# SAM9X75D5M device description
Architecture: ARM926EJ-S; Family: SAM9; Series: SAM9X7
Registers are 32-bit, read-write, reset 0x0 unless marked. A register's access mark holds for its fields unless they carry their own. Offsets are from the block's base; [hi:lo] are bit positions; {n}, {i} and the like mark numbered series; 'fields as' and 'values as' point back to an identical list.

## DSI — LCD Controller
Instances: DSI 0xF8054000
0x04 DSI_PWR_UP — Power-Up Control Register
  [0] SHUTDOWNZ — Shutdown
    0=DSI host is reset; 1=DSI host is powered up
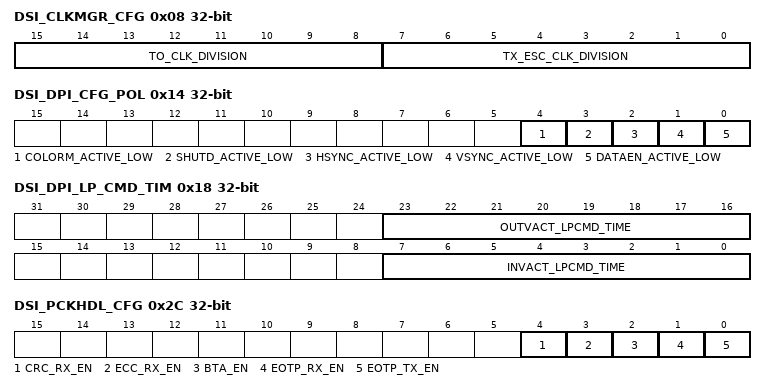
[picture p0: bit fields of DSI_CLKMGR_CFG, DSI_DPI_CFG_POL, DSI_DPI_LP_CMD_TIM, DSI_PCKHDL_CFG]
0x08 DSI_CLKMGR_CFG — Clock Management Configuration Register
  [15:8] TO_CLK_DIVISION — Timeout Clock Division
  [7:0] TX_ESC_CLK_DIVISION — Transmission Escape Clock Division
0x0C DSI_DPI_VCID — Input Video Virtual Channel ID Configuration Register
  [1:0] DPI_VCID — Input Video Virtual Channel Identifier
0x10 DSI_DPI_COLOR_CODING — Input Video Color Coding Configuration Register
  [3:0] DPI_COLOR_CODING — Input Video Color Coding
    0=16BIT_CFG1 (16-bit configuration 1); 1=16BIT_CFG2 (16-bit configuration 2); 2=16BIT_CFG3 (16-bit configuration 3); 3=18BIT_CFG1 (18-bit configuration 1); 4=18BIT_CFG2 (18-bit configuration 2); 5=24BIT
0x14 DSI_DPI_CFG_POL — Input Video Polarity Configuration Register
  [4] COLORM_ACTIVE_LOW — Color Mode Signal Active Low
    0=Input interface Color Mode signal is active high; 1=Input interface Color Mode signal is active low
  [3] SHUTD_ACTIVE_LOW — Shutdown Signal Active Low
    0=Input interface Shutdown signal is active high; 1=Input interface Shutdown signal is active low
  [2] HSYNC_ACTIVE_LOW — Horizontal Synchronisation Signal Active Low
    0=Input video interface VSYNC is active high; 1=Input video interface VSYNC is active low
  [1] VSYNC_ACTIVE_LOW — Vertical Synchronisation Signal Active Low
    values as HSYNC_ACTIVE_LOW
  [0] DATAEN_ACTIVE_LOW — Data Enable Signal Active Low
    0=Input video interface DATAEN is active high; 1=Input video interface DATAEN is active low
0x18 DSI_DPI_LP_CMD_TIM — Input Video Timing for Low-Power Commands Configuration Register
  [23:16] OUTVACT_LPCMD_TIME — Output Vertical Active Low-Power Command
  [7:0] INVACT_LPCMD_TIME — Input Vertical Active Low-Power Command Time
0x2C DSI_PCKHDL_CFG — DSI Protocol Configuration Register
  [4] CRC_RX_EN — CRC Reception Enable
    0=Disables the CRC reception and error reporting; 1=Enables the CRC reception and error reporting
  [3] ECC_RX_EN — ECC Reception Enable
    0=Disables the ECC reception, error correction, and reporting; 1=Enables the ECC reception, error correction, and reporting
  [2] BTA_EN — Bus Turn-Around Enable
    0=Disables the Bus Turnaround (BTA) request; 1=Enables the Bus Turnaround (BTA) request
  [1] EOTP_RX_EN — End Of Reception Packet Enable
    0=Disables the EoTp reception; 1=Enables the EoTp reception
  [0] EOTP_TX_EN — End Of Transmission Packet Enable
    0=Disables the EoTp transmission; 1=Enables the EoTp transmission
0x30 DSI_GEN_VCID — Read Generic Virtual Channel ID Configuration Register
  [1:0] GEN_VCID_RX — Generic Reception Virtual Channel Identifier
0x34 DSI_MODE_CFG — Mode of Operation Configuration Register
  [0] CMD_VIDEO_MODE — Command/Video Mode
    0=Video mode; 1=Command mode
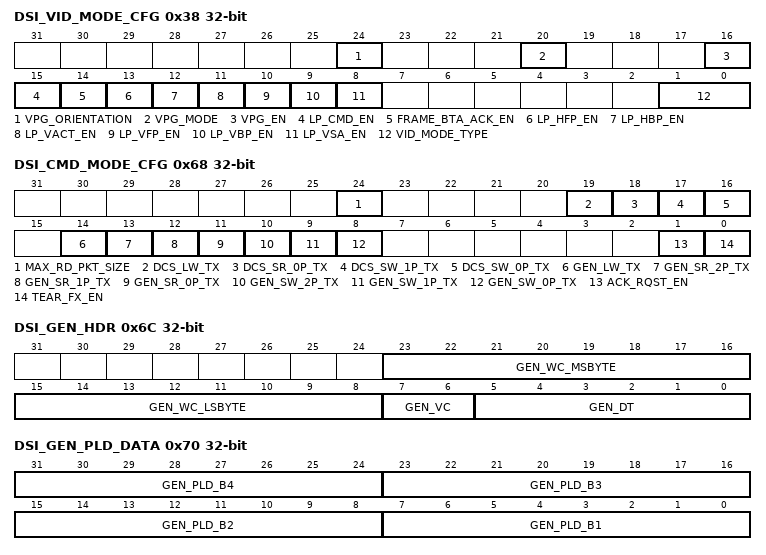
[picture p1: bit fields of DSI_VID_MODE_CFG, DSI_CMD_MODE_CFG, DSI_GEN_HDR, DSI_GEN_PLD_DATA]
0x38 DSI_VID_MODE_CFG — Video Mode Configuration Register
  [24] VPG_ORIENTATION — Video Pattern Generator Orientation
    0=Vertical color bar orientation; 1=Horizontal color bar orientation
  [20] VPG_MODE — Video Pattern Generator Mode
    0=Color bar (horizontal or vertical) pattern is selected; 1=BER pattern (vertical only) is selected
  [16] VPG_EN — Video Pattern Generator Enable
    0=Disables the video mode pattern generator; 1=Enables the video mode pattern generator
  [15] LP_CMD_EN — Low Power Command Transmission Enable
    0=Disables the command transmission only in Low-Power mode; 1=Enables the command transmission only in Low-Power mode
  [14] FRAME_BTA_ACK_EN — Frame Bus Turn Around Acknowledge Enable
    0=Disables the request for an acknowledge response at the end of a frame; 1=Enables the request for an acknowledge response at the end of a frame
  [13] LP_HFP_EN — Low-Power Horizontal Front Porch Enable
    0=Disables the return to low-power inside the HFP period when timing allows; 1=Enables the return to low-power inside the HFP period when timing allows
  [12] LP_HBP_EN — Low-Power Horizontal Back Porch Enable
    0=Disables the return to low-power inside the HBP period when timing allows; 1=Enables the return to low-power inside the HBP period when timing allows
  [11] LP_VACT_EN — Low-Power Vertical Active Enable
    0=Disables the return to low-power inside the VACT period when timing allows; 1=Enables the return to low-power inside the VACT period when timing allows
  [10] LP_VFP_EN — Low-Power Vertical Front Porch Enable
    0=Disables the return to low-power inside the VFP period when timing allows; 1=Enables the return to low-power inside the VFP period when timing allows
  [9] LP_VBP_EN — Low-Power Vertical Back Porch Enable
    0=Disables the return to low-power inside the VBP period when timing allows; 1=Enables the return to low-power inside the VBP period when timing allows
  [8] LP_VSA_EN — Low-Power Vertical Sync Active Enable
    0=Disables the return to low-power inside the VSA period when timing allows; 1=Enables the return to low-power inside the VSA period when timing allows
  [1:0] VID_MODE_TYPE — Video Mode Transmission Type
    0=Non-burst with sync pulses; 1=Non-burst with sync events; 2=Burst mode; 3=Burst mode
0x3C DSI_VID_PKT_SIZE — Video Mode packet size Configuration Register
  [13:0] VID_PKT_SIZE — Video Mode Packet Size
0x40 DSI_VID_NUM_CHUNKS — Video Mode Number of Chunks Configuration Register
  [12:0] VID_NUM_CHUNKS — Video Mode Number of Chunks
0x44 DSI_VID_NULL_SIZE — Video Mode Null Packets Size Configuration Register
  [12:0] VID_NULL_SIZE — Video Mode Null Packet Size
0x48 DSI_VID_HSA_TIME — Video Mode HSA Time Configuration Register
  [11:0] VID_HSA_TIME — Video Mode Horizontal Sync Active Time
0x4C DSI_VID_HBP_TIME — Video Mode HBP Time Configuration Register
  [11:0] VID_HBP_TIME — Video Mode Horizontal Back Porch Time
0x50 DSI_VID_HLINE_TIME — Video Mode HLINE Time Configuration Register
  [14:0] VID_HLINE_TIME — Video Mode Horizontal Line Time
0x54 DSI_VID_VSA_LINES — Video Mode VSA Lines Configuration Register
  [9:0] VSA_LINES — Vertical Sync Active Lines
0x58 DSI_VID_VBP_LINES — Video Mode VBP Lines Configuration Register
  [9:0] VBP_LINES — Vertical Back Porch Lines
0x5C DSI_VID_VFP_LINES — Video Mode VFP Lines Configuration Register
  [9:0] VFP_LINES — Video Mode Vertical Front Porch Lines
0x60 DSI_VID_VACTIVE_LINES — Video Mode VACTIVE Lines Configuration Register
  [13:0] V_ACTIVE_LINES — Video Mode Active Lines
0x68 DSI_CMD_MODE_CFG — Command Mode Configuration Register
  [24] MAX_RD_PKT_SIZE — Maximum Read Packet Size
    0=High-speed; 1=Low-power
  [19] DCS_LW_TX — DCS Long Write Packet Transmission Type
    0=High-speed; 1=Low-power
  [18] DCS_SR_0P_TX — DCS Short Read Packet 0 Transmission Type
    0=High-speed; 1=Low-power
  [17] DCS_SW_1P_TX — DCS Short Write Packet 1 Transmission Type
    0=High-speed; 1=Low-power
  [16] DCS_SW_0P_TX — DCS Short Write Packet 0 Transmission Type
    0=High-speed; 1=Low-power
  [14] GEN_LW_TX — Generic Long Write Packet Transmission Type
    0=High-speed; 1=Low-power
  [13] GEN_SR_2P_TX — Generic Short Read Packet 2 Transmission Type
    0=High-speed; 1=Low-power
  [12] GEN_SR_1P_TX — Generic Short Read Packet 1 Transmission Type
    0=High-speed; 1=Low-power
  [11] GEN_SR_0P_TX — Generic Short Read Packet 0 Transmission Type
    0=High-speed; 1=Low-power
  [10] GEN_SW_2P_TX — Generic Short Write Packet 2 Transmission Type
    0=High-speed; 1=Low-power
  [9] GEN_SW_1P_TX — Generic Short Write Packet 1 Transmission Type
    0=High-speed; 1=Low-power
  [8] GEN_SW_0P_TX — Generic Short Write Packet 0 Transmission Type
    0=High-speed; 1=Low-power
  [1] ACK_RQST_EN — Acknowledge Request Enable
    0=Disables the acknowledge request after each packet transmission; 1=Enables the acknowledge request after each packet transmission
  [0] TEAR_FX_EN — Tearing Effect Enable
    0=Disables the tearing effect acknowledge request; 1=Enables the tearing effect acknowledge request
0x6C DSI_GEN_HDR — Generic Interface Header Register
  [23:16] GEN_WC_MSBYTE — Generic Interface Word Count Most Significant Byte
  [15:8] GEN_WC_LSBYTE — Generic Interface Word Count Least Significant Byte
  [7:6] GEN_VC — Generic Interface Virtual Channel
  [5:0] GEN_DT — Generic Interface Data Type
0x70 DSI_GEN_PLD_DATA — Generic Interface Payload Register
  [8n-1:8n-8] GEN_PLD_B{n} (n=1..4) — Generic Interface Payload Byte {n}
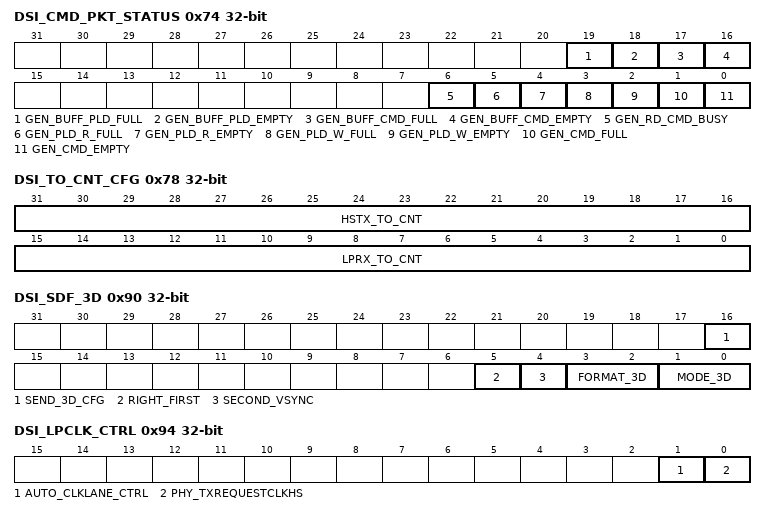
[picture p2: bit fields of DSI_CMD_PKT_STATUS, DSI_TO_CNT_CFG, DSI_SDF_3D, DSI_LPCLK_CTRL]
0x74 DSI_CMD_PKT_STATUS ro — Command Packet Status Register
  [19] GEN_BUFF_PLD_FULL — Generic Payload Internal Buffer Full
  [18] GEN_BUFF_PLD_EMPTY — Generic Payload Internal Buffer Empty
  [17] GEN_BUFF_CMD_FULL — Generic Command Internal Buffer Full
  [16] GEN_BUFF_CMD_EMPTY — Generic Command Internal Buffer Empty
  [6] GEN_RD_CMD_BUSY — Generic Interface Read Command FIFO Busy
  [5] GEN_PLD_R_FULL — Generic Interface Read Payload FIFO Full
  [4] GEN_PLD_R_EMPTY — Generic Interface Read Payload FIFO Empty
  [3] GEN_PLD_W_FULL — Generic Interface Write Payload FIFO Full
  [2] GEN_PLD_W_EMPTY — Generic Interface Write Payload FIFO Empty
  [1] GEN_CMD_FULL — Generic Interface Command FIFO Full
  [0] GEN_CMD_EMPTY — Generic Interface Command FIFO Empty
0x78 DSI_TO_CNT_CFG — Timeout Counters Configuration Register
  [31:16] HSTX_TO_CNT — High-Speed Transmission Timeout Counter
  [15:0] LPRX_TO_CNT — Low-Power Reception Timeout Counter
0x7C DSI_HS_RD_TO_CNT — HS Read Response Timeout Counter Configuration Register
  [15:0] HS_RD_TO_CNT — High-Speed Read Operation Timeout Counter
0x80 DSI_LP_RD_TO_CNT — LP Read Response Timeout Counter Configuration Register
  [15:0] LP_RD_TO_CNT — Low-Power Read Operation Timeout Counter
0x84 DSI_HS_WR_TO_CNT — HS Write Response Timeout Counter Configuration Register
  [15:0] HS_WR_TO_CNT — High-Speed Write Operation Timeout Counter
0x88 DSI_LP_WR_TO_CNT — LP Write Response Timeout Counter Configuration Register
  [15:0] LP_WR_TO_CNT — Low-Power Write Operation Timeout Counter
0x8C DSI_BTA_TO_CNT — BTA Response Timeout Counter Configuration Register
  [15:0] BTA_TO_CNT — Bus Turn Around Timeout Counter
0x90 DSI_SDF_3D — VSS Packet 3D Control Register
  [16] SEND_3D_CFG — Send 3D Configuration Enable
  [5] RIGHT_FIRST
    0=Left eye is sent first, then right eye; 1=Right eye data is sent first, then left eye
  [4] SECOND_VSYNC — Second Vertical Sync Enable
    0=No sync pulses between left and right data; 1=Sync pulse (HSYNC, VSYNC, blanking) between left and right data
  [3:2] FORMAT_3D — 3D Format
    0=Line (alternating lines of left and right data); 1=Frame (alternating frames of left and right data); 2=Pixel (alternating pixels of left and right data)
  [1:0] MODE_3D — 3D Mode
    0=3D mode off (2D mode on); 1=3D mode on, portrait orientation; 2=3D mode on, landscape orientation
0x94 DSI_LPCLK_CTRL — Clock Lane Control Register
  [1] AUTO_CLKLANE_CTRL — Automatic Clock Lane Control
    0=Disables the automatic mechanism to stop providing the clock in the clock lane when time allows; 1=Enables the automatic mechanism to stop providing clock in the clock lane when time allows
  [0] PHY_TXREQUESTCLKHS — D-PHY High-Speed Transmission Request
    0=Disables High-Speed mode transmission request on clock lane; 1=Enables High-Speed mode transmission request on clock lane
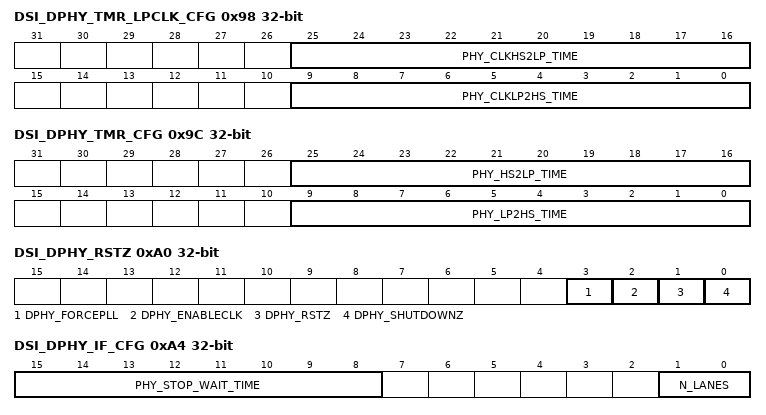
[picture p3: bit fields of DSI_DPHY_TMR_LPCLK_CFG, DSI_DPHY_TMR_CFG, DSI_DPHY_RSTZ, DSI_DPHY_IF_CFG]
0x98 DSI_DPHY_TMR_LPCLK_CFG — Clock Lane Switch Mode Timing Configuration Register
  [25:16] PHY_CLKHS2LP_TIME — D-PHY Clock High-Speed to Low-Power Time
  [9:0] PHY_CLKLP2HS_TIME — D-PHY Clock Low-Power to High-Speed Time
0x9C DSI_DPHY_TMR_CFG — Data Lane Switch Mode Timing Configuration Register
  [25:16] PHY_HS2LP_TIME — D-PHY Data High-Speed to Low-Power Time
  [9:0] PHY_LP2HS_TIME — D-PHY Data Low-Power to High-Speed Time
0xA0 DSI_DPHY_RSTZ — Reset and PLL Control Register
  [3] DPHY_FORCEPLL — D-PHY Force PLL Enable
    0=Disables the D-PHY PLL when the D-PHY is in ULPS; 1=Enables the D-PHY PLL when the D-PHY is in ULPS
  [2] DPHY_ENABLECLK — D-PHY Enable Clock Lane
    0=Disables the D-PHY clock lane module; 1=Enables the D-PHY clock lane module
  [1] DPHY_RSTZ — D-PHY Reset Disable
    0=Places the digital section of the D-PHY in the reset state; 1=Allows the digital section of the D-PHY to leave the reset state
  [0] DPHY_SHUTDOWNZ — D-PHY Shutdown Disable
    0=Places the complete D-PHY macro in power-down state; 1=Allow the complete D-PHY macro to leave power-down state
0xA4 DSI_DPHY_IF_CFG — D-PHY Interface Configuration Register
  [15:8] PHY_STOP_WAIT_TIME — D-PHY Stop State Wait Time
  [1:0] N_LANES — Number of Active Data Lanes
    0=One data lane (lane 0); 1=Two data lanes (lanes 0 and 1); 2=Three data lanes (lanes 0, 1, and 2); 3=Four data lanes (lanes 0, 1, 2, and 3)
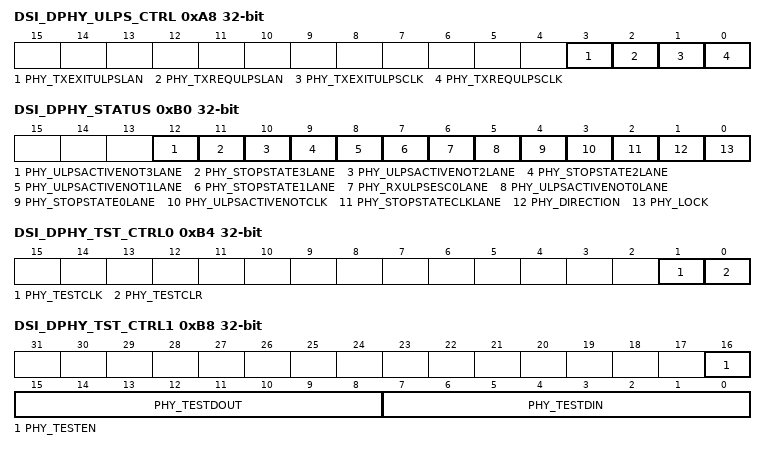
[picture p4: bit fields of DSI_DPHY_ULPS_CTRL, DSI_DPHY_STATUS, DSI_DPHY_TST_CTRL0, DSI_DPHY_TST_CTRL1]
0xA8 DSI_DPHY_ULPS_CTRL — D-PHY ULPS Control Register
  [3] PHY_TXEXITULPSLAN — D-PHY Ultra-Low-Power Exit Transmission on Data Lane
    0=No effect; 1=ULPS mode exit on clock lane
  [2] PHY_TXREQULPSLAN — D-PHY Ultra-Low-Power Request Transmission on Data Lane
    0=No effect; 1=ULPS mode request on data lane
  [1] PHY_TXEXITULPSCLK — D-PHY Ultra-Low-Power Exit Transmission on Clock Lane
    0=No effect; 1=ULPS mode exit on clock lane
  [0] PHY_TXREQULPSCLK — D-PHY Ultra-Low-Power Request Transmission on Clock Lane
    0=No effect; 1=ULPS mode request on clock lane
0xAC DSI_DPHY_TX_TRIGGERS — D-PHY Tx Trigger Control Register
  [3:0] PHY_TX_TRIGGERS — D-PHY Trigger Transmission
0xB0 DSI_DPHY_STATUS ro — D-PHY Status Register
  [12] PHY_ULPSACTIVENOT3LANE — D-PHY Ultra-Low-Power State Active on Data Lane 3 Status
    0=Data lane 3 is in Ultra-Low-Power state; 1=Data lane 3 is not in Ultra-Low-Power (ULP) state
  [11] PHY_STOPSTATE3LANE — D-PHY Stop State on Data Lane 3 Status
    0=Data lane 3 module is not in Stop state; 1=Data lane 3 module is in Stop state
  [10] PHY_ULPSACTIVENOT2LANE — D-PHY Ultra-Low-Power State Active on Data Lane 2 Status
    0=Data lane 2 is in Ultra-Low-Power state; 1=Data lane 2 is not in Ultra-Low-Power (ULP) state
  [9] PHY_STOPSTATE2LANE — D-PHY Stop State on Data Lane 2 Status
    0=Data lane 2 module is not in Stop state; 1=Data lane 2 module is in Stop state
  [8] PHY_ULPSACTIVENOT1LANE — D-PHY Ultra-Low-Power State Active on Data Lane 1 Status
    0=Data lane 1 is in Ultra-Low-Power state; 1=Data lane 1 is not in Ultra-Low-Power (ULP) state
  [7] PHY_STOPSTATE1LANE — D-PHY Stop State on Data Lane 1 Statu
    0=Data lane 1 module is not in Stop state; 1=Data lane 1 module is in Stop state
  [6] PHY_RXULPSESC0LANE — Ultra-Low-Power State Escape Code Reception
    0=Data lane 0 is not in Ultra Low-Power state after reception of the Ultra Low-Power state Escape code; 1=Data lane 0 is in Ultra Low-Power state after reception of the Ultra Low-Power state Escape code
  [5] PHY_ULPSACTIVENOT0LANE — D-PHY Ultra-Low-Power State Active on Data Lane 0 Status
    0=Data lane 0 is in Ultra-Low-Power state; 1=Data lane 0 is not in Ultra-Low-Power (ULP) state
  [4] PHY_STOPSTATE0LANE — D-PHY Stop State on Data Lane 0 Status
    0=Data lane 0 module is not in Stop state; 1=Data lane 0 module is in Stop state
  [3] PHY_ULPSACTIVENOTCLK — D-PHY Ultra-Low-Power State Active on Clock Lane Status
    0=The clock lane is in Ultra-Low-Power state; 1=The clock lane is not in Ultra-Low-Power (ULP) state
  [2] PHY_STOPSTATECLKLANE — D-PHY Stop State Clock Lane Status
    0=The clock lane module is not in Stop state; 1=The clock lane module is in Stop state
  [1] PHY_DIRECTION — D-PHY Direction Status
    0=The lane interconnect is in Transmit mode; 1=The lane interconnect is in Receive mode
  [0] PHY_LOCK — D-PHY Lock Status
0xB4 DSI_DPHY_TST_CTRL0 — D-PHY Control Register 0
  [1] PHY_TESTCLK — D-PHY Test Interface Clock
  [0] PHY_TESTCLR — D-PHY Test Interface Clear
    0=No effect; 1=Clears the PHY test interface
0xB8 DSI_DPHY_TST_CTRL1 — D-PHY Control Register 1
  [16] PHY_TESTEN — D-PHY Test Interface Operation Type
    0=WRITEADDR (The data write operation is set on the rising edge of DSI_DPHY_TST_CTRL0.PHY_TESTCLK.); 1=WRITEDATA (The address write operation is set on the falling edge of DSI_DPHY_TST_CTRL0.PHY_TESTCLK.)
  [15:8] PHY_TESTDOUT — D-PHY Test Interface Data Out
  [7:0] PHY_TESTDIN — D-PHY Test Interface Data In
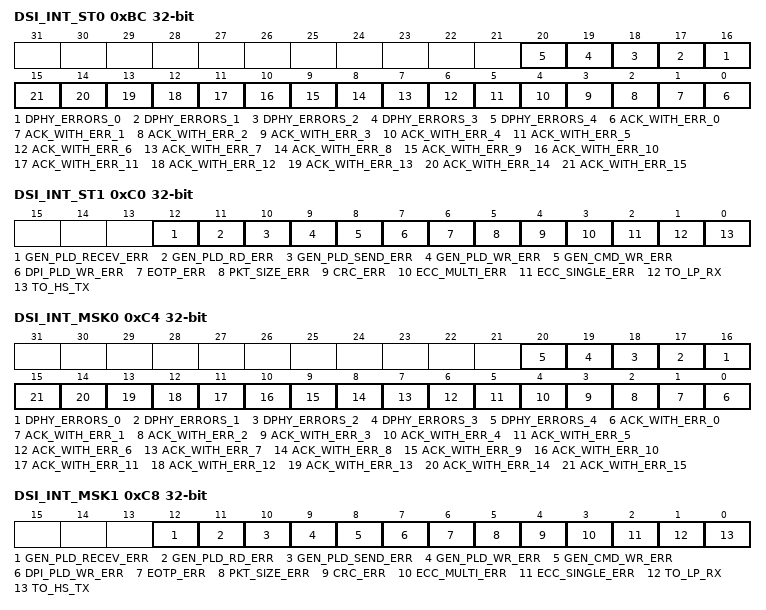
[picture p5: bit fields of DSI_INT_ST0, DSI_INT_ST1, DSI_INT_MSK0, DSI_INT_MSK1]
0xBC DSI_INT_ST0 ro — Interrupt Status Register 0
  [n+16] DPHY_ERRORS_{n} (n=0..4)
  [n] ACK_WITH_ERR_{n} (n=0..15) — Acknowledge With Error {n}
0xC0 DSI_INT_ST1 ro — Interrupt Status Register 1
  [12] GEN_PLD_RECEV_ERR — Generic Interface Payload Receive Error Status
  [11] GEN_PLD_RD_ERR — Generic Interface DCS Payload Read Error Status
  [10] GEN_PLD_SEND_ERR — Generic Interface Payload Send Error Status
  [9] GEN_PLD_WR_ERR — Generic Interface Payload Write Error Status
  [8] GEN_CMD_WR_ERR — Generic Interface Command Write Error Status
  [7] DPI_PLD_WR_ERR — Input Video Payload Write Error Status
  [6] EOTP_ERR — End Of Transmission Packet Error Status
  [5] PKT_SIZE_ERR — Packet Size Error Status
  [4] CRC_ERR — CRC Error Status
  [3] ECC_MULTI_ERR — ECC Multiple Error Status
  [2] ECC_SINGLE_ERR — ECC Single Error Status
  [1] TO_LP_RX — Low-Power Reception Timeout Status
  [0] TO_HS_TX — High-Speed Transmission Timeout Status
0xC4 DSI_INT_MSK0 — Interrupt Mask Configuration Register 0
  [n+16] DPHY_ERRORS_{n} (n=0..4) — D-PHY Errors Lane {n} Mask
  [n] ACK_WITH_ERR_{n} (n=0..15) — Acknowledge With Error {n} Mask
0xC8 DSI_INT_MSK1 — Interrupt Mask Configuration Register 1
  [12] GEN_PLD_RECEV_ERR — Generic Interface Payload Receive Error Mask
  [11] GEN_PLD_RD_ERR — Generic Interface Payload Read Error Mask
  [10] GEN_PLD_SEND_ERR — Generic Interface Payload Send Error Mask
  [9] GEN_PLD_WR_ERR — Generic Interface Payload Write Error Mask
  [8] GEN_CMD_WR_ERR — Generic Interface Command Write Error Mask
  [7] DPI_PLD_WR_ERR — Input Video Payload Write Error Mask
  [6] EOTP_ERR — End Of Transmission Packet Error Mask
  [5] PKT_SIZE_ERR — Packet Size Error Mask
  [4] CRC_ERR — CRC Error Mask
  [3] ECC_MULTI_ERR — ECC Multiple Error Mask
  [2] ECC_SINGLE_ERR — ECC Single Error Mask
  [1] TO_LP_RX — Timeout Low-Power Reception Mask
  [0] TO_HS_TX — Timeout High-Speed Transmission Mask
0xCC DSI_DPHY_CAL — D-PHY Calibration Control Register
  [0] TXSKEWCALHS — Transmission Skew Calibration High-Speed
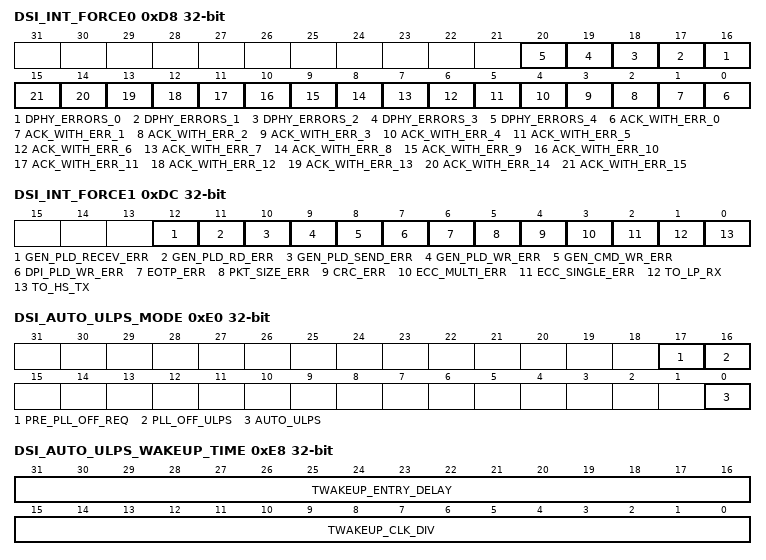
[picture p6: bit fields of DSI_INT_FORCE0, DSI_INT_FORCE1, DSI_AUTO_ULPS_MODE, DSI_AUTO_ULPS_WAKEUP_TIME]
0xD8 DSI_INT_FORCE0 — Interrupt Force Control Register 0
  [n+16] DPHY_ERRORS_{n} (n=0..4) — D-PHY Errors {n} Force
  [n] ACK_WITH_ERR_{n} (n=0..15) — Acknowledge With Error {n} Force
0xDC DSI_INT_FORCE1 — Interrupt Force Control Register 1
  [12] GEN_PLD_RECEV_ERR — Generic Interface Payload Receive Error Force
  [11] GEN_PLD_RD_ERR — Generic Interface Payload Read Error Force
  [10] GEN_PLD_SEND_ERR — Generic Interface Payload Send Error Force
  [9] GEN_PLD_WR_ERR — Generic Interface Payload Write Error Force
  [8] GEN_CMD_WR_ERR — Generic Interface Command Write Error Force
  [7] DPI_PLD_WR_ERR — Input Video Interface Payload Write Error Force
  [6] EOTP_ERR — End Of Transmission Packet Error Force
  [5] PKT_SIZE_ERR — Packet Size error Force
  [4] CRC_ERR — CRC Error Force
  [3] ECC_MULTI_ERR — ECC Multiple Error Force
  [2] ECC_SINGLE_ERR — ECC Single Error Force
  [1] TO_LP_RX — Timeout Low-Power Reception Force
  [0] TO_HS_TX — Timeout High-Speed Transmission Force
0xE0 DSI_AUTO_ULPS_MODE — Automatic Ultra-Low-Power Mode Register
  [17] PRE_PLL_OFF_REQ — Automatic Ultra-Low-Power Enable
    0=No effect; 1=When pll_off_ulps is active, allows to turn off PLL before the request to enter ULPS
  [16] PLL_OFF_ULPS — PLL Turned OFF During Ultra-Low-Power
    0=Prevents turning off the D-PHY PLL during ULPS; 1=Turns off the D-PHY PLL during ULPS
  [0] AUTO_ULPS — Automatic Ultra-Low-Power Enable
    0=Disables the automatic mechanism to enter and exit ULPS; 1=Enables the automatic mechanism to enter and exit ULPS
0xE4 DSI_AUTO_ULPS_ENTRY_DELAY — Automatic Ultra-Low-Power Entry Delay Register
  [31:0] ULPS_ENTRY_DELAY — Ultra-Low-Power Enable Entry Delay
0xE8 DSI_AUTO_ULPS_WAKEUP_TIME — Automatic Ultra-Low-Power Wake-Up Time Register
  [31:16] TWAKEUP_ENTRY_DELAY — Wake-Up Time Entry Delay
  [15:0] TWAKEUP_CLK_DIV — Wake-Up Time Clock Divider
0xF4 DSI_DPHY_TMR_RD_CFG — DHY Read Timing Configuration Register
  [15:0] MAX_RD_TIME — Maximum Read Time
0xF8 DSI_AUTO_ULPS_MIN_TIME — Automatic Ultra-Low-Power Minimum Time Register
  [11:0] ULPS_MIN_TIME — Ultra-Low-Power Minimum Time
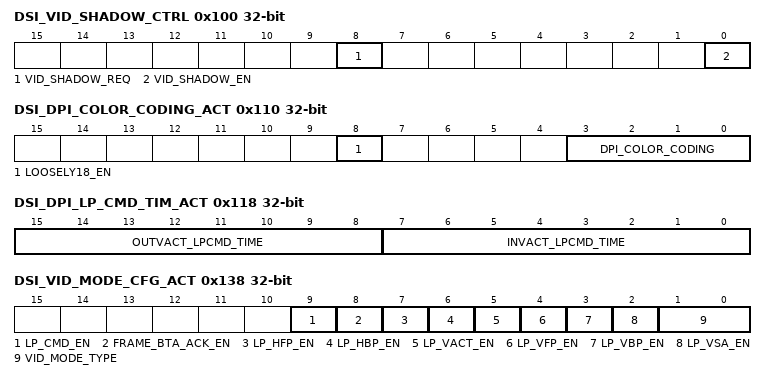
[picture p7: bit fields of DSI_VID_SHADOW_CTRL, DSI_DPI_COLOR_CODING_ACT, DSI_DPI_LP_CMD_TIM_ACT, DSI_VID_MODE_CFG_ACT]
0x100 DSI_VID_SHADOW_CTRL — Video Mode Shadow Feature Control Register
  [8] VID_SHADOW_REQ — Video Interface Shadow Request
    0=No effect; 1=Requests that the input video interface registers from regbank are copied to the auxiliary registers. When the request is completed, this bit is automatically cleared.
  [0] VID_SHADOW_EN — Video Interface Shadow Registers Enable
    0=No effect; 1=Input video bus receives the active configuration from the auxiliary registers. When the feature is set at the same time as VID_SHADOW_REQ, the auxiliary registers are automatically updated.
0x10C DSI_DPI_VCID_ACT ro — Input Video Virtual Channel ID Active Value Register
  [1:0] DPI_VCID — Input Video Interface Virtual Channel Identifier
0x110 DSI_DPI_COLOR_CODING_ACT ro — Input Video Color Coding Active Value Register
  [8] LOOSELY18_EN — Loosely Packed Variant to 18-bit Enable
    0=Disables loosely packed variant to 18-bit configurations; 1=Enables loosely packed variant to 18-bit configurations
  [3:0] DPI_COLOR_CODING — Input Video Interface Color Coding
    values as DSI_DPI_COLOR_CODING.DPI_COLOR_CODING
0x118 DSI_DPI_LP_CMD_TIM_ACT ro — Input Video Timing for Low-Power Commands Active Value Register
  [15:8] OUTVACT_LPCMD_TIME — Output Vertical Active Low-Power Command Time
  [7:0] INVACT_LPCMD_TIME — Input Vertical Active Low-Power Command Time
0x138 DSI_VID_MODE_CFG_ACT ro — Video Mode Active Value Register
  [9] LP_CMD_EN — Low-Power Command Enable
    values as DSI_VID_MODE_CFG.LP_CMD_EN
  [8] FRAME_BTA_ACK_EN — Frame Bus Turn Around Acknowledge Enable
    values as DSI_VID_MODE_CFG.FRAME_BTA_ACK_EN
  [7] LP_HFP_EN — Low-Power Horizontal Front Porch Enable
    0=Disables return to low-power inside the HFP period when timing allows; 1=Enables the return to low-power inside the HFP period when timing allows
  [6] LP_HBP_EN — Low-Power Horizontal Back Porch Enable
    values as DSI_VID_MODE_CFG.LP_HBP_EN
  [5] LP_VACT_EN — Low-Power Vertical Active Enable
    values as DSI_VID_MODE_CFG.LP_VACT_EN
  [4] LP_VFP_EN — Low-Power Vertical Front Porch Enable
    values as DSI_VID_MODE_CFG.LP_VFP_EN
  [3] LP_VBP_EN — Low-Power Vertical Back Porch Enable
    values as DSI_VID_MODE_CFG.LP_VBP_EN
  [2] LP_VSA_EN — Low-Power Vertical Sync Active Enable
    values as DSI_VID_MODE_CFG.LP_VSA_EN
  [1:0] VID_MODE_TYPE — Video Mode Type
    values as DSI_VID_MODE_CFG.VID_MODE_TYPE
0x13C DSI_VID_PKT_SIZE_ACT ro — Video Mode packet size Active Value Register
  [13:0] VID_PKT_SIZE — Video Mode Packet Size
0x140 DSI_VID_NUM_CHUNKS_ACT ro — Video Mode Number of Chunks Active Value Register
  [12:0] VID_NUM_CHUNKS — Video Mode Number of Chunks
0x144 DSI_VID_NULL_SIZE_ACT ro — Video Mode Null Packets Size Active Value Register
  [12:0] VID_NULL_SIZE — Video Mode Null Packet Size
0x148 DSI_VID_HSA_TIME_ACT ro — Video Mode HSA Time Active Value Register
  [11:0] VID_HSA_TIME — Video Mode Horizontal Sync Active Time
0x14C DSI_VID_HBP_TIME_ACT ro — Video Mode HBP Time Active Value Register
  [11:0] VID_HBP_TIME — Video Mode Horizontal Back Porch Time
0x150 DSI_VID_HLINE_TIME_ACT ro — Video Mode HLINE Time Active Value Register
  [15:0] VID_HLINE_TIME — Video Mode Horizontal Line Time
0x154 DSI_VID_VSA_LINES_ACT ro — Video Mode VSA Lines Active Value Register
  [9:0] VSA_LINES — Video Mode Vertical Sync Active Lines
0x158 DSI_VID_VBP_LINES_ACT ro — Video Mode VBP Lines Active Value Register
  [9:0] VBP_LINES — Video Mode Vertical Back Porch Lines
0x15C DSI_VID_VFP_LINES_ACT ro — Video Mode VFP Lines Active Value Register
  [9:0] VFP_LINES — Video Mode Vertical Front Porch Lines
0x160 DSI_VID_VACTIVE_LINES_ACT ro — Video Mode VACTIVE Lines Active Value Register
  [13:0] V_ACTIVE_LINES — Video Mode Vertical Active Lines
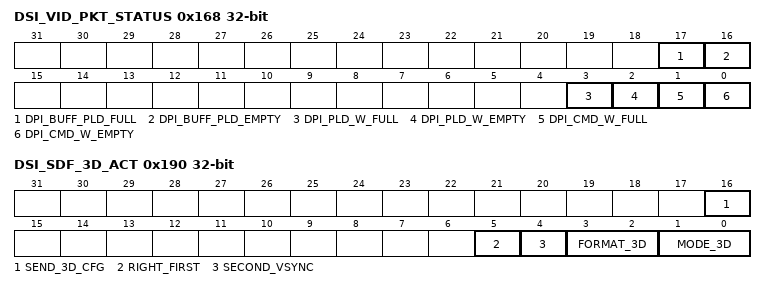
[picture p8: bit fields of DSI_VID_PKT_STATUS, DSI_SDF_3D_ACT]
0x168 DSI_VID_PKT_STATUS ro — Video Mode Packet Status Register
  [17] DPI_BUFF_PLD_FULL — Input Video Interface Write Payload Fifo Full
  [16] DPI_BUFF_PLD_EMPTY — Input Video Interface Write Payload Fifo Empty
  [3] DPI_PLD_W_FULL — Input Video Interface Write Payload Fifo Full
  [2] DPI_PLD_W_EMPTY — Input Video Interface Write Payload Fifo Empty
  [1] DPI_CMD_W_FULL — Input Video Interface Command Fifo Full
  [0] DPI_CMD_W_EMPTY — Input Video Interface Command Fifo Empty
0x190 DSI_SDF_3D_ACT ro — VSS Packet 3D Active Value Register
  [16] SEND_3D_CFG — Send 3D Configuration Enable
  [5] RIGHT_FIRST
    values as DSI_SDF_3D.RIGHT_FIRST
  [4] SECOND_VSYNC — Second Vertical Sync Enable
    values as DSI_SDF_3D.SECOND_VSYNC
  [3:2] FORMAT_3D — 3D Format
    values as DSI_SDF_3D.FORMAT_3D
  [1:0] MODE_3D — 3D Mode
    0=3D Mode off (2D Mode on); 1=3D Mode on, portrait orientation; 2=3D Mode on, landscape orientation

## Notices in the file
Copyright (c) 2021 Microchip Technology Inc.
SPDX-License-Identifier: Apache-2.0
Licensed under the Apache License, Version 2.0 (the "License");
you may not use this file except in compliance with the License.
You may obtain a copy of the License at
http://www.apache.org/licenses/LICENSE-2.0
Unless required by applicable law or agreed to in writing, software
distributed under the License is distributed on an "AS IS" BASIS,
WITHOUT WARRANTIES OR CONDITIONS OF ANY KIND, either express or implied.
See the License for the specific language governing permissions and
limitations under the License.
